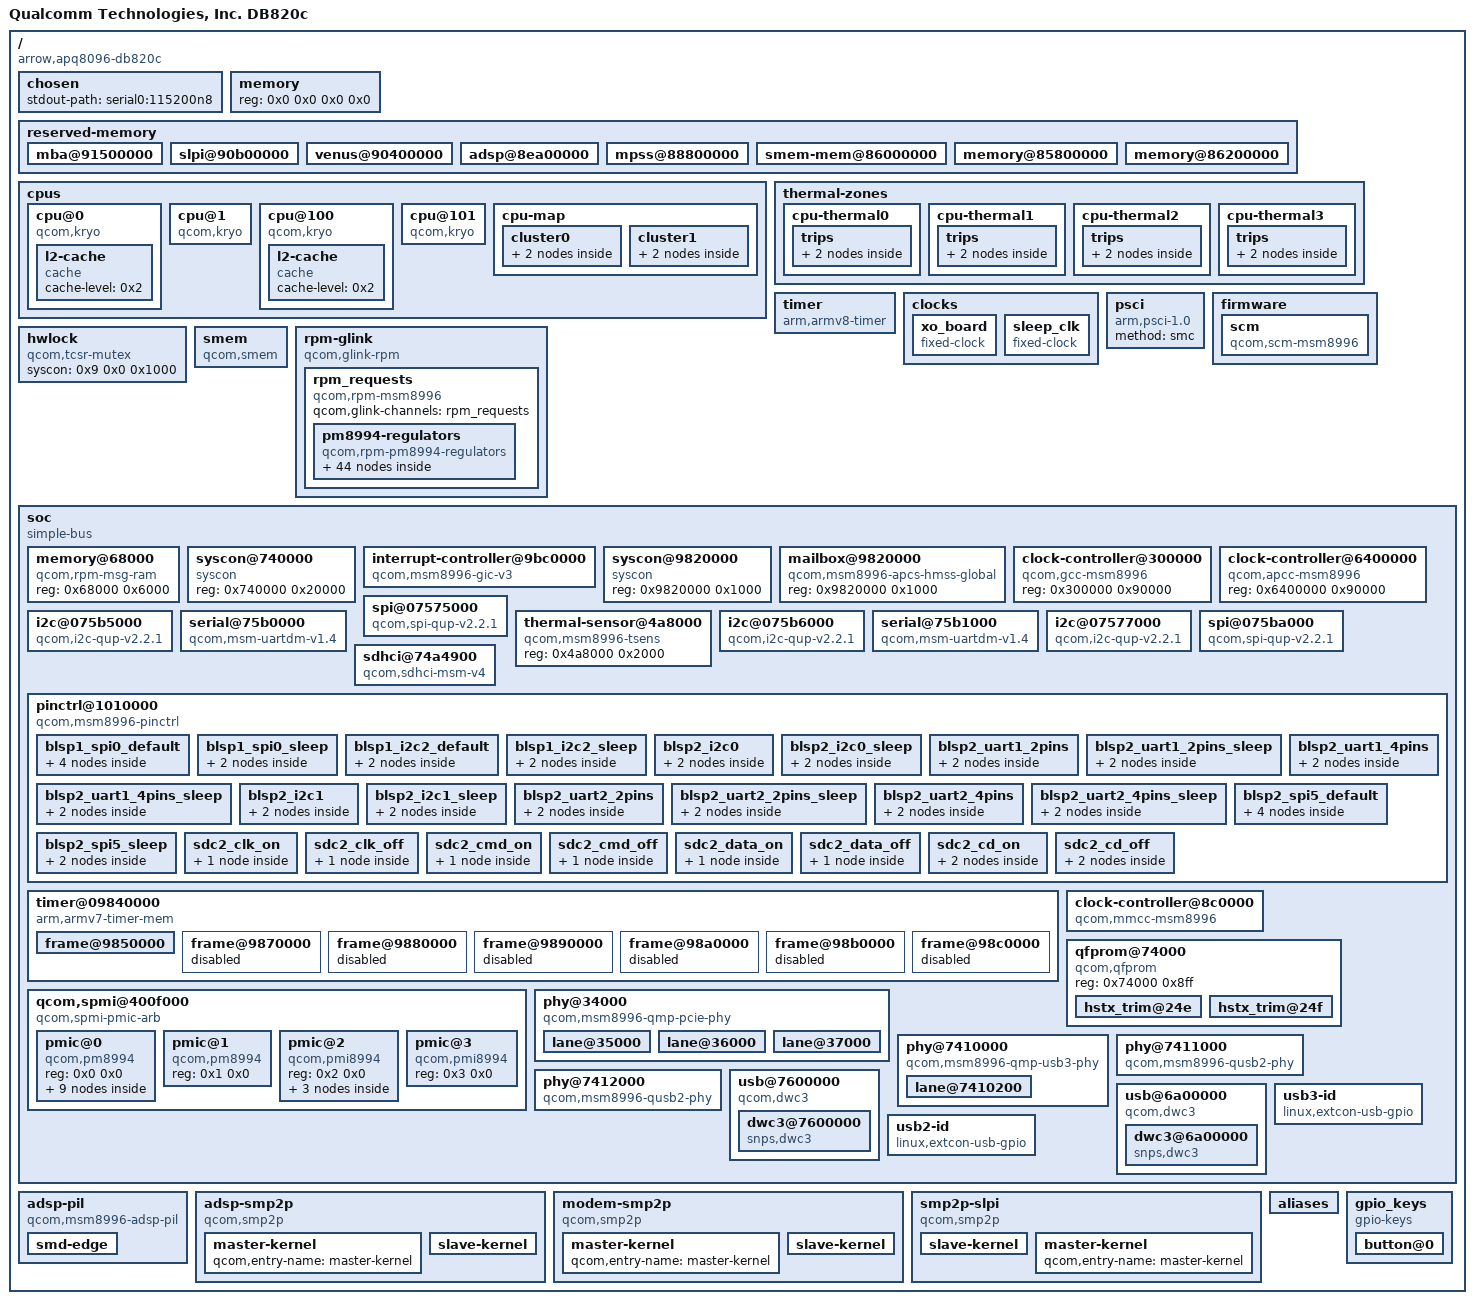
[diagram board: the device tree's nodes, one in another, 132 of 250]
/dts-v1/;

/ {
	model = "Qualcomm Technologies, Inc. DB820c";
	interrupt-parent = <0x1>;
	#address-cells = <0x2>;
	#size-cells = <0x2>;
	compatible = "arrow,apq8096-db820c", "qcom,apq8096-sbc";

	chosen {
		stdout-path = "serial0:115200n8";
	};

	memory {
		device_type = "memory";
		reg = <0x0 0x0 0x0 0x0>;
	};

	reserved-memory {
		#address-cells = <0x2>;
		#size-cells = <0x2>;
		ranges;

		mba@91500000 {
			reg = <0x0 0x91500000 0x0 0x200000>;
			no-map;
			phandle = <0x3e>;
		};

		slpi@90b00000 {
			reg = <0x0 0x90b00000 0x0 0xa00000>;
			no-map;
			phandle = <0x3f>;
		};

		venus@90400000 {
			reg = <0x0 0x90400000 0x0 0x700000>;
			no-map;
			phandle = <0x40>;
		};

		adsp@8ea00000 {
			reg = <0x0 0x8ea00000 0x0 0x1a00000>;
			no-map;
			phandle = <0x3a>;
		};

		mpss@88800000 {
			reg = <0x0 0x88800000 0x0 0x6200000>;
			no-map;
			phandle = <0x41>;
		};

		smem-mem@86000000 {
			reg = <0x0 0x86000000 0x0 0x200000>;
			no-map;
			phandle = <0xa>;
		};

		memory@85800000 {
			reg = <0x0 0x85800000 0x0 0x800000>;
			no-map;
		};

		memory@86200000 {
			reg = <0x0 0x86200000 0x0 0x2600000>;
			no-map;
		};
	};

	cpus {
		#address-cells = <0x2>;
		#size-cells = <0x0>;

		cpu@0 {
			device_type = "cpu";
			compatible = "qcom,kryo";
			reg = <0x0 0x0>;
			enable-method = "psci";
			next-level-cache = <0x2>;
			phandle = <0x4>;

			l2-cache {
				compatible = "cache";
				cache-level = <0x2>;
				phandle = <0x2>;
			};
		};

		cpu@1 {
			device_type = "cpu";
			compatible = "qcom,kryo";
			reg = <0x0 0x1>;
			enable-method = "psci";
			next-level-cache = <0x2>;
			phandle = <0x5>;
		};

		cpu@100 {
			device_type = "cpu";
			compatible = "qcom,kryo";
			reg = <0x0 0x100>;
			enable-method = "psci";
			next-level-cache = <0x3>;
			phandle = <0x6>;

			l2-cache {
				compatible = "cache";
				cache-level = <0x2>;
				phandle = <0x3>;
			};
		};

		cpu@101 {
			device_type = "cpu";
			compatible = "qcom,kryo";
			reg = <0x0 0x101>;
			enable-method = "psci";
			next-level-cache = <0x3>;
			phandle = <0x7>;
		};

		cpu-map {

			cluster0 {

				core0 {
					cpu = <0x4>;
				};

				core1 {
					cpu = <0x5>;
				};
			};

			cluster1 {

				core0 {
					cpu = <0x6>;
				};

				core1 {
					cpu = <0x7>;
				};
			};
		};
	};

	thermal-zones {

		cpu-thermal0 {
			polling-delay-passive = <0xfa>;
			polling-delay = <0x3e8>;
			thermal-sensors = <0x8 0x3>;

			trips {

				trip0 {
					temperature = <0x124f8>;
					hysteresis = <0x7d0>;
					type = "passive";
					phandle = <0x42>;
				};

				trip1 {
					temperature = <0x1adb0>;
					hysteresis = <0x7d0>;
					type = "critical";
					phandle = <0x43>;
				};
			};
		};

		cpu-thermal1 {
			polling-delay-passive = <0xfa>;
			polling-delay = <0x3e8>;
			thermal-sensors = <0x8 0x5>;

			trips {

				trip0 {
					temperature = <0x124f8>;
					hysteresis = <0x7d0>;
					type = "passive";
					phandle = <0x44>;
				};

				trip1 {
					temperature = <0x1adb0>;
					hysteresis = <0x7d0>;
					type = "critical";
					phandle = <0x45>;
				};
			};
		};

		cpu-thermal2 {
			polling-delay-passive = <0xfa>;
			polling-delay = <0x3e8>;
			thermal-sensors = <0x8 0x8>;

			trips {

				trip0 {
					temperature = <0x124f8>;
					hysteresis = <0x7d0>;
					type = "passive";
					phandle = <0x46>;
				};

				trip1 {
					temperature = <0x1adb0>;
					hysteresis = <0x7d0>;
					type = "critical";
					phandle = <0x47>;
				};
			};
		};

		cpu-thermal3 {
			polling-delay-passive = <0xfa>;
			polling-delay = <0x3e8>;
			thermal-sensors = <0x8 0xa>;

			trips {

				trip0 {
					temperature = <0x124f8>;
					hysteresis = <0x7d0>;
					type = "passive";
					phandle = <0x48>;
				};

				trip1 {
					temperature = <0x1adb0>;
					hysteresis = <0x7d0>;
					type = "critical";
					phandle = <0x49>;
				};
			};
		};
	};

	timer {
		compatible = "arm,armv8-timer";
		interrupts = <0x1 0xd 0xf08 0x1 0xe 0xf08 0x1 0xb 0xf08 0x1 0xa 0xf08>;
	};

	clocks {

		xo_board {
			compatible = "fixed-clock";
			#clock-cells = <0x0>;
			clock-frequency = <0x124f800>;
			clock-output-names = "xo_board";
			phandle = <0x1f>;
		};

		sleep_clk {
			compatible = "fixed-clock";
			#clock-cells = <0x0>;
			clock-frequency = <0x7ffc>;
			clock-output-names = "sleep_clk";
			phandle = <0x4a>;
		};
	};

	psci {
		compatible = "arm,psci-1.0";
		method = "smc";
	};

	firmware {

		scm {
			compatible = "qcom,scm-msm8996";
		};
	};

	hwlock {
		compatible = "qcom,tcsr-mutex";
		syscon = <0x9 0x0 0x1000>;
		#hwlock-cells = <0x1>;
		phandle = <0xb>;
	};

	smem {
		compatible = "qcom,smem";
		memory-region = <0xa>;
		hwlocks = <0xb 0x3>;
	};

	rpm-glink {
		compatible = "qcom,glink-rpm";
		interrupts = <0x0 0xa8 0x1>;
		qcom,rpm-msg-ram = <0xc>;
		mboxes = <0xd 0x0>;

		rpm_requests {
			compatible = "qcom,rpm-msm8996";
			qcom,glink-channels = "rpm_requests";

			pm8994-regulators {
				compatible = "qcom,rpm-pm8994-regulators";
				vdd_l1-supply = <0xe>;
				vdd_l2_l26_l28-supply = <0xe>;
				vdd_l3_l11-supply = <0xe>;
				vdd_l4_l27_l31-supply = <0xe>;
				vdd_l5_l7-supply = <0xf>;
				vdd_l14_l15-supply = <0xf>;
				vdd_l20_l21-supply = <0xf>;
				vdd_l25-supply = <0xe>;

				s1 {
					phandle = <0x4b>;
				};

				s2 {
					phandle = <0x4c>;
				};

				s3 {
					regulator-min-microvolt = <0x13d620>;
					regulator-max-microvolt = <0x13d620>;
					phandle = <0xe>;
				};

				s4 {
					regulator-min-microvolt = <0x1b7740>;
					regulator-max-microvolt = <0x1b7740>;
					phandle = <0x4d>;
				};

				s5 {
					regulator-min-microvolt = <0x20ce70>;
					regulator-max-microvolt = <0x20ce70>;
					phandle = <0xf>;
				};

				s6 {
					phandle = <0x4e>;
				};

				s7 {
					regulator-min-microvolt = <0xc3500>;
					regulator-max-microvolt = <0xc3500>;
					phandle = <0x4f>;
				};

				s8 {
					phandle = <0x50>;
				};

				s9 {
					phandle = <0x51>;
				};

				s10 {
					phandle = <0x52>;
				};

				s11 {
					phandle = <0x53>;
				};

				s12 {
					phandle = <0x54>;
				};

				l1 {
					regulator-min-microvolt = <0xf4240>;
					regulator-max-microvolt = <0xf4240>;
					phandle = <0x55>;
				};

				l2 {
					regulator-min-microvolt = <0x1312d0>;
					regulator-max-microvolt = <0x1312d0>;
					phandle = <0x56>;
				};

				l3 {
					regulator-min-microvolt = <0xcf850>;
					regulator-max-microvolt = <0xcf850>;
					phandle = <0x57>;
				};

				l4 {
					regulator-min-microvolt = <0x12b128>;
					regulator-max-microvolt = <0x12b128>;
					phandle = <0x58>;
				};

				l5 {
					phandle = <0x59>;
				};

				l6 {
					regulator-min-microvolt = <0x124f80>;
					regulator-max-microvolt = <0x124f80>;
					phandle = <0x5a>;
				};

				l7 {
					phandle = <0x5b>;
				};

				l8 {
					regulator-min-microvolt = <0x1b7740>;
					regulator-max-microvolt = <0x1b7740>;
					phandle = <0x5c>;
				};

				l9 {
					regulator-min-microvolt = <0x1b7740>;
					regulator-max-microvolt = <0x1b7740>;
					phandle = <0x5d>;
				};

				l10 {
					regulator-min-microvolt = <0x1b7740>;
					regulator-max-microvolt = <0x1b7740>;
					phandle = <0x5e>;
				};

				l11 {
					regulator-min-microvolt = <0x118c30>;
					regulator-max-microvolt = <0x118c30>;
					phandle = <0x5f>;
				};

				l12 {
					regulator-min-microvolt = <0x1b7740>;
					regulator-max-microvolt = <0x1b7740>;
					phandle = <0x2c>;
				};

				l13 {
					regulator-min-microvolt = <0x1b7740>;
					regulator-max-microvolt = <0x2d0370>;
					phandle = <0x60>;
				};

				l14 {
					regulator-min-microvolt = <0x1b7740>;
					regulator-max-microvolt = <0x1b7740>;
					phandle = <0x61>;
				};

				l15 {
					regulator-min-microvolt = <0x1b7740>;
					regulator-max-microvolt = <0x1b7740>;
					phandle = <0x62>;
				};

				l16 {
					regulator-min-microvolt = <0x2932e0>;
					regulator-max-microvolt = <0x2932e0>;
					phandle = <0x63>;
				};

				l17 {
					regulator-min-microvolt = <0x2625a0>;
					regulator-max-microvolt = <0x2625a0>;
					phandle = <0x64>;
				};

				l18 {
					regulator-min-microvolt = <0x2932e0>;
					regulator-max-microvolt = <0x2c4020>;
					phandle = <0x65>;
				};

				l19 {
					regulator-min-microvolt = <0x2dc6c0>;
					regulator-max-microvolt = <0x2dc6c0>;
					phandle = <0x66>;
				};

				l20 {
					regulator-min-microvolt = <0x2d0370>;
					regulator-max-microvolt = <0x2d0370>;
					regulator-allow-set-load;
					phandle = <0x67>;
				};

				l21 {
					regulator-min-microvolt = <0x2d0370>;
					regulator-max-microvolt = <0x2d0370>;
					phandle = <0x68>;
				};

				l22 {
					regulator-min-microvolt = <0x325aa0>;
					regulator-max-microvolt = <0x325aa0>;
					phandle = <0x69>;
				};

				l23 {
					regulator-min-microvolt = <0x2ab980>;
					regulator-max-microvolt = <0x2ab980>;
					phandle = <0x6a>;
				};

				l24 {
					regulator-min-microvolt = <0x2eebb8>;
					regulator-max-microvolt = <0x2eebb8>;
					phandle = <0x2d>;
				};

				l25 {
					regulator-min-microvolt = <0x124f80>;
					regulator-max-microvolt = <0x124f80>;
					regulator-allow-set-load;
					phandle = <0x6b>;
				};

				l26 {
					phandle = <0x6c>;
				};

				l27 {
					regulator-min-microvolt = <0xf4240>;
					regulator-max-microvolt = <0xf4240>;
					phandle = <0x6d>;
				};

				l28 {
					regulator-min-microvolt = <0xe1d48>;
					regulator-max-microvolt = <0xe1d48>;
					regulator-allow-set-load;
					phandle = <0x2b>;
				};

				l29 {
					regulator-min-microvolt = <0x2ab980>;
					regulator-max-microvolt = <0x2ab980>;
					phandle = <0x6e>;
				};

				l30 {
					regulator-min-microvolt = <0x1b7740>;
					regulator-max-microvolt = <0x1b7740>;
					phandle = <0x6f>;
				};

				l31 {
					phandle = <0x70>;
				};

				l32 {
					regulator-min-microvolt = <0x1b7740>;
					regulator-max-microvolt = <0x1b7740>;
					phandle = <0x71>;
				};
			};
		};
	};

	soc {
		#address-cells = <0x1>;
		#size-cells = <0x1>;
		ranges = <0x0 0x0 0x0 0xffffffff>;
		compatible = "simple-bus";
		phandle = <0x72>;

		memory@68000 {
			compatible = "qcom,rpm-msg-ram";
			reg = <0x68000 0x6000>;
			phandle = <0xc>;
		};

		syscon@740000 {
			compatible = "syscon";
			reg = <0x740000 0x20000>;
			phandle = <0x9>;
		};

		interrupt-controller@9bc0000 {
			compatible = "qcom,msm8996-gic-v3", "arm,gic-v3";
			#interrupt-cells = <0x3>;
			interrupt-controller;
			#redistributor-regions = <0x1>;
			redistributor-stride = <0x0 0x40000>;
			reg = <0x9bc0000 0x10000 0x9c00000 0x100000>;
			interrupts = <0x1 0x9 0x4>;
			phandle = <0x1>;
		};

		syscon@9820000 {
			compatible = "syscon";
			reg = <0x9820000 0x1000>;
			phandle = <0x3c>;
		};

		mailbox@9820000 {
			compatible = "qcom,msm8996-apcs-hmss-global";
			reg = <0x9820000 0x1000>;
			#mbox-cells = <0x1>;
			phandle = <0xd>;
		};

		clock-controller@300000 {
			compatible = "qcom,gcc-msm8996";
			#clock-cells = <0x1>;
			#reset-cells = <0x1>;
			#power-domain-cells = <0x1>;
			reg = <0x300000 0x90000>;
			phandle = <0x10>;
		};

		clock-controller@6400000 {
			compatible = "qcom,apcc-msm8996";
			reg = <0x6400000 0x90000>;
			#clock-cells = <0x1>;
			phandle = <0x73>;
		};

		spi@07575000 {
			compatible = "qcom,spi-qup-v2.2.1";
			reg = <0x7575000 0x600>;
			interrupts = <0x0 0x5f 0x4>;
			clocks = <0x10 0x6f 0x10 0x6d>;
			clock-names = "core", "iface";
			pinctrl-names = "default", "sleep";
			pinctrl-0 = <0x11>;
			pinctrl-1 = <0x12>;
			#address-cells = <0x1>;
			#size-cells = <0x0>;
			status = "okay";
			label = "LS-SPI0";
			phandle = <0x74>;
		};

		i2c@075b5000 {
			compatible = "qcom,i2c-qup-v2.2.1";
			reg = <0x75b5000 0x1000>;
			interrupts = <0x0 0x65 0x0>;
			clocks = <0x10 0x81 0x10 0x84>;
			clock-names = "iface", "core";
			pinctrl-names = "default", "sleep";
			pinctrl-0 = <0x13>;
			pinctrl-1 = <0x14>;
			#address-cells = <0x1>;
			#size-cells = <0x0>;
			status = "okay";
			label = "HS-I2C2";
			phandle = <0x75>;
		};

		thermal-sensor@4a8000 {
			compatible = "qcom,msm8996-tsens";
			reg = <0x4a8000 0x2000>;
			#thermal-sensor-cells = <0x1>;
			phandle = <0x8>;
		};

		serial@75b0000 {
			compatible = "qcom,msm-uartdm-v1.4", "qcom,msm-uartdm";
			reg = <0x75b0000 0x1000>;
			interrupts = <0x0 0x72 0x4>;
			clocks = <0x10 0x88 0x10 0x81>;
			clock-names = "core", "iface";
			status = "okay";
			label = "LS-UART1";
			pinctrl-names = "default", "sleep";
			pinctrl-0 = <0x15>;
			pinctrl-1 = <0x16>;
			phandle = <0x76>;
		};

		i2c@075b6000 {
			compatible = "qcom,i2c-qup-v2.2.1";
			reg = <0x75b6000 0x1000>;
			interrupts = <0x0 0x66 0x0>;
			clocks = <0x10 0x81 0x10 0x87>;
			clock-names = "iface", "core";
			pinctrl-names = "default", "sleep";
			pinctrl-0 = <0x17>;
			pinctrl-1 = <0x18>;
			#address-cells = <0x1>;
			#size-cells = <0x0>;
			status = "okay";
			label = "LS-I2C1";
			phandle = <0x77>;
		};

		serial@75b1000 {
			compatible = "qcom,msm-uartdm-v1.4", "qcom,msm-uartdm";
			reg = <0x75b1000 0x1000>;
			interrupts = <0x0 0x73 0x4>;
			clocks = <0x10 0x8b 0x10 0x81>;
			clock-names = "core", "iface";
			status = "okay";
			label = "LS-UART0";
			pinctrl-names = "default", "sleep";
			pinctrl-0 = <0x19>;
			pinctrl-1 = <0x1a>;
			phandle = <0x78>;
		};

		i2c@07577000 {
			compatible = "qcom,i2c-qup-v2.2.1";
			reg = <0x7577000 0x1000>;
			interrupts = <0x0 0x61 0x0>;
			clocks = <0x10 0x6d 0x10 0x76>;
			clock-names = "iface", "core";
			pinctrl-names = "default", "sleep";
			pinctrl-0 = <0x1b>;
			pinctrl-1 = <0x1c>;
			#address-cells = <0x1>;
			#size-cells = <0x0>;
			status = "okay";
			label = "LS-I2C0";
			phandle = <0x79>;
		};

		spi@075ba000 {
			compatible = "qcom,spi-qup-v2.2.1";
			reg = <0x75ba000 0x600>;
			interrupts = <0x0 0x6a 0x4>;
			clocks = <0x10 0x92 0x10 0x81>;
			clock-names = "core", "iface";
			pinctrl-names = "default", "sleep";
			pinctrl-0 = <0x1d>;
			pinctrl-1 = <0x1e>;
			#address-cells = <0x1>;
			#size-cells = <0x0>;
			status = "okay";
			label = "HS-SPI1";
			phandle = <0x7a>;
		};

		sdhci@74a4900 {
			status = "okay";
			compatible = "qcom,sdhci-msm-v4";
			reg = <0x74a4900 0x314 0x74a4000 0x800>;
			reg-names = "hc_mem", "core_mem";
			interrupts = <0x0 0x7d 0x0 0x0 0xdd 0x0>;
			interrupt-names = "hc_irq", "pwr_irq";
			clock-names = "iface", "core", "xo";
			clocks = <0x10 0x68 0x10 0x67 0x1f>;
			bus-width = <0x4>;
			pinctrl-names = "default", "sleep";
			pinctrl-0 = <0x20 0x21 0x22 0x23>;
			pinctrl-1 = <0x24 0x25 0x26 0x27>;
			cd-gpios = <0x28 0x26 0x1>;
			phandle = <0x7b>;
		};

		pinctrl@1010000 {
			compatible = "qcom,msm8996-pinctrl";
			reg = <0x1010000 0x300000>;
			interrupts = <0x0 0xd0 0x4>;
			gpio-controller;
			#gpio-cells = <0x2>;
			interrupt-controller;
			#interrupt-cells = <0x2>;
			phandle = <0x28>;

			blsp1_spi0_default {
				phandle = <0x11>;

				pinmux {
					function = "blsp_spi1";
					pins = "gpio0", "gpio1", "gpio3";
				};

				pinmux_cs {
					function = "gpio";
					pins = "gpio2";
				};

				pinconf {
					pins = "gpio0", "gpio1", "gpio3";
					drive-strength = <0xc>;
					bias-disable;
				};

				pinconf_cs {
					pins = "gpio2";
					drive-strength = <0x10>;
					bias-disable;
					output-high;
				};
			};

			blsp1_spi0_sleep {
				phandle = <0x12>;

				pinmux {
					function = "gpio";
					pins = "gpio0", "gpio1", "gpio2", "gpio3";
				};

				pinconf {
					pins = "gpio0", "gpio1", "gpio2", "gpio3";
					drive-strength = <0x2>;
					bias-pull-down;
				};
			};

			blsp1_i2c2_default {
				phandle = <0x1b>;

				pinmux {
					function = "blsp_i2c3";
					pins = "gpio47", "gpio48";
				};

				pinconf {
					pins = "gpio47", "gpio48";
					drive-strength = <0x10>;
					bias-disable = <0x0>;
				};
			};

			blsp1_i2c2_sleep {
				phandle = <0x1c>;

				pinmux {
					function = "gpio";
					pins = "gpio47", "gpio48";
				};

				pinconf {
					pins = "gpio47", "gpio48";
					drive-strength = <0x2>;
					bias-disable = <0x0>;
				};
			};

			blsp2_i2c0 {
				phandle = <0x13>;

				pinmux {
					function = "blsp_i2c7";
					pins = "gpio55", "gpio56";
				};

				pinconf {
					pins = "gpio55", "gpio56";
					drive-strength = <0x10>;
					bias-disable;
				};
			};

			blsp2_i2c0_sleep {
				phandle = <0x14>;

				pinmux {
					function = "gpio";
					pins = "gpio55", "gpio56";
				};

				pinconf {
					pins = "gpio55", "gpio56";
					drive-strength = <0x2>;
					bias-disable;
				};
			};

			blsp2_uart1_2pins {
				phandle = <0x15>;

				pinmux {
					function = "blsp_uart8";
					pins = "gpio4", "gpio5";
				};

				pinconf {
					pins = "gpio4", "gpio5";
					drive-strength = <0x10>;
					bias-disable;
				};
			};

			blsp2_uart1_2pins_sleep {
				phandle = <0x16>;

				pinmux {
					function = "gpio";
					pins = "gpio4", "gpio5";
				};

				pinconf {
					pins = "gpio4", "gpio5";
					drive-strength = <0x2>;
					bias-disable;
				};
			};

			blsp2_uart1_4pins {
				phandle = <0x7c>;

				pinmux {
					function = "blsp_uart8";
					pins = "gpio4", "gpio5", "gpio6", "gpio7";
				};

				pinconf {
					pins = "gpio4", "gpio5", "gpio6", "gpio7";
					drive-strength = <0x10>;
					bias-disable;
				};
			};

			blsp2_uart1_4pins_sleep {
				phandle = <0x7d>;

				pinmux {
					function = "gpio";
					pins = "gpio4", "gpio5", "gpio6", "gpio7";
				};

				pinconf {
					pins = "gpio4", "gpiio5", "gpio6", "gpio7";
					drive-strength = <0x2>;
					bias-disable;
				};
			};

			blsp2_i2c1 {
				phandle = <0x17>;

				pinmux {
					function = "blsp_i2c8";
					pins = "gpio6", "gpio7";
				};

				pinconf {
					pins = "gpio6", "gpio7";
					drive-strength = <0x10>;
					bias-disable;
				};
			};

			blsp2_i2c1_sleep {
				phandle = <0x18>;

				pinmux {
					function = "gpio";
					pins = "gpio6", "gpio7";
				};

				pinconf {
					pins = "gpio6", "gpio7";
					drive-strength = <0x2>;
					bias-disable;
				};
			};

			blsp2_uart2_2pins {
				phandle = <0x7e>;

				pinmux {
					function = "blsp_uart9";
					pins = "gpio49", "gpio50";
				};

				pinconf {
					pins = "gpio49", "gpio50";
					drive-strength = <0x10>;
					bias-disable;
				};
			};

			blsp2_uart2_2pins_sleep {
				phandle = <0x7f>;

				pinmux {
					function = "gpio";
					pins = "gpio49", "gpio50";
				};

				pinconf {
					pins = "gpio49", "gpio50";
					drive-strength = <0x2>;
					bias-disable;
				};
			};

			blsp2_uart2_4pins {
				phandle = <0x19>;

				pinmux {
					function = "blsp_uart9";
					pins = "gpio49", "gpio50", "gpio51", "gpio52";
				};

				pinconf {
					pins = "gpio49", "gpio50", "gpio51", "gpio52";
					drive-strength = <0x10>;
					bias-disable;
				};
			};

			blsp2_uart2_4pins_sleep {
				phandle = <0x1a>;

				pinmux {
					function = "gpio";
					pins = "gpio49", "gpio50", "gpio51", "gpio52";
				};

				pinconf {
					pins = "gpio49", "gpio50", "gpio51", "gpio52";
					drive-strength = <0x2>;
					bias-disable;
				};
			};

			blsp2_spi5_default {
				phandle = <0x1d>;

				pinmux {
					function = "blsp_spi12";
					pins = "gpio85", "gpio86", "gpio88";
				};

				pinmux_cs {
					function = "gpio";
					pins = "gpio87";
				};

				pinconf {
					pins = "gpio85", "gpio86", "gpio88";
					drive-strength = <0xc>;
					bias-disable;
				};

				pinconf_cs {
					pins = "gpio87";
					drive-strength = <0x10>;
					bias-disable;
					output-high;
				};
			};

			blsp2_spi5_sleep {
				phandle = <0x1e>;

				pinmux {
					function = "gpio";
					pins = "gpio85", "gpio86", "gpio87", "gpio88";
				};

				pinconf {
					pins = "gpio85", "gpio86", "gpio87", "gpio88";
					drive-strength = <0x2>;
					bias-pull-down;
				};
			};

			sdc2_clk_on {
				phandle = <0x20>;

				config {
					pins = "sdc2_clk";
					bias-disable;
					drive-strength = <0x10>;
				};
			};

			sdc2_clk_off {
				phandle = <0x24>;

				config {
					pins = "sdc2_clk";
					bias-disable;
					drive-strength = <0x2>;
				};
			};

			sdc2_cmd_on {
				phandle = <0x21>;

				config {
					pins = "sdc2_cmd";
					bias-pull-up;
					drive-strength = <0xa>;
				};
			};

			sdc2_cmd_off {
				phandle = <0x25>;

				config {
					pins = "sdc2_cmd";
					bias-pull-up;
					drive-strength = <0x2>;
				};
			};

			sdc2_data_on {
				phandle = <0x22>;

				config {
					pins = "sdc2_data";
					bias-pull-up;
					drive-strength = <0xa>;
				};
			};

			sdc2_data_off {
				phandle = <0x26>;

				config {
					pins = "sdc2_data";
					bias-pull-up;
					drive-strength = <0x2>;
				};
			};

			sdc2_cd_on {
				phandle = <0x23>;

				mux {
					pins = "gpio38";
					function = "gpio";
				};

				config {
					pins = "gpio38";
					bias-pull-up;
					drive-strength = <0x10>;
				};
			};

			sdc2_cd_off {
				phandle = <0x27>;

				mux {
					pins = "gpio38";
					function = "gpio";
				};

				config {
					pins = "gpio38";
					bias-pull-up;
					drive-strength = <0x2>;
				};
			};
		};

		timer@09840000 {
			#address-cells = <0x1>;
			#size-cells = <0x1>;
			ranges;
			compatible = "arm,armv7-timer-mem";
			reg = <0x9840000 0x1000>;
			clock-frequency = <0x124f800>;

			frame@9850000 {
				frame-number = <0x0>;
				interrupts = <0x0 0x1f 0x4 0x0 0x1e 0x4>;
				reg = <0x9850000 0x1000 0x9860000 0x1000>;
			};

			frame@9870000 {
				frame-number = <0x1>;
				interrupts = <0x0 0x20 0x4>;
				reg = <0x9870000 0x1000>;
				status = "disabled";
			};

			frame@9880000 {
				frame-number = <0x2>;
				interrupts = <0x0 0x21 0x4>;
				reg = <0x9880000 0x1000>;
				status = "disabled";
			};

			frame@9890000 {
				frame-number = <0x3>;
				interrupts = <0x0 0x22 0x4>;
				reg = <0x9890000 0x1000>;
				status = "disabled";
			};

			frame@98a0000 {
				frame-number = <0x4>;
				interrupts = <0x0 0x23 0x4>;
				reg = <0x98a0000 0x1000>;
				status = "disabled";
			};

			frame@98b0000 {
				frame-number = <0x5>;
				interrupts = <0x0 0x24 0x4>;
				reg = <0x98b0000 0x1000>;
				status = "disabled";
			};

			frame@98c0000 {
				frame-number = <0x6>;
				interrupts = <0x0 0x25 0x4>;
				reg = <0x98c0000 0x1000>;
				status = "disabled";
			};
		};

		qcom,spmi@400f000 {
			compatible = "qcom,spmi-pmic-arb";
			reg = <0x400f000 0x1000 0x4400000 0x800000 0x4c00000 0x800000 0x5800000 0x200000 0x400a000 0x2100>;
			reg-names = "core", "chnls", "obsrvr", "intr", "cnfg";
			interrupt-names = "periph_irq";
			interrupts = <0x0 0x146 0x4>;
			qcom,ee = <0x0>;
			qcom,channel = <0x0>;
			#address-cells = <0x2>;
			#size-cells = <0x0>;
			interrupt-controller;
			#interrupt-cells = <0x4>;
			phandle = <0x80>;

			pmic@0 {
				compatible = "qcom,pm8994", "qcom,spmi-pmic";
				reg = <0x0 0x0>;
				#address-cells = <0x1>;
				#size-cells = <0x0>;

				rtc@6000 {
					compatible = "qcom,pm8941-rtc";
					reg = <0x6000 0x6100>;
					reg-names = "rtc", "alarm";
					interrupts = <0x0 0x61 0x1 0x1>;
				};

				gpios@c000 {
					compatible = "qcom,pm8994-gpio";
					reg = <0xc000>;
					gpio-controller;
					#gpio-cells = <0x2>;
					interrupts = <0x0 0xc0 0x0 0x0 0x0 0xc1 0x0 0x0 0x0 0xc2 0x0 0x0 0x0 0xc3 0x0 0x0 0x0 0xc4 0x0 0x0 0x0 0xc5 0x0 0x0 0x0 0xc6 0x0 0x0 0x0 0xc7 0x0 0x0 0x0 0xc8 0x0 0x0 0x0 0xc9 0x0 0x0 0x0 0xca 0x0 0x0 0x0 0xcb 0x0 0x0 0x0 0xcc 0x0 0x0 0x0 0xcd 0x0 0x0 0x0 0xce 0x0 0x0 0x0 0xcf 0x0 0x0 0x0 0xd0 0x0 0x0 0x0 0xd1 0x0 0x0 0x0 0xd2 0x0 0x0 0x0 0xd3 0x0 0x0 0x0 0xd4 0x0 0x0 0x0 0xd5 0x0 0x0>;
					pinctrl-names = "default";
					pinctrl-0 = <0x29>;
					phandle = <0x35>;

					pm8994_gpio5 {
						phandle = <0x29>;

						pinconf {
							pins = "gpio5";
							output-low;
							power-source = <0x2>;
						};
					};

					pm8996_gpio2 {
						phandle = <0x3d>;

						pinconf {
							pins = "gpio2";
							function = "normal";
							input-enable;
							drive-push-pull;
							bias-pull-up;
							qcom,drive-strength = <0x0>;
							power-source = <0x2>;
						};
					};

					pm8996_gpio22 {
						phandle = <0x36>;

						pinconf {
							pins = "gpio22";
							function = "normal";
							input-enable;
							bias-pull-down;
							qcom,drive-strength = <0x0>;
							power-source = <0x2>;
						};
					};
				};

				mpps@a000 {
					compatible = "qcom,pm8994-mpp";
					reg = <0xa000>;
					gpio-controller;
					#gpio-cells = <0x2>;
					interrupts = <0x0 0xa0 0x0 0x0 0x0 0xa1 0x0 0x0 0x0 0xa2 0x0 0x0 0x0 0xa3 0x0 0x0 0x0 0xa4 0x0 0x0 0x0 0xa5 0x0 0x0 0x0 0xa6 0x0 0x0 0x0 0xa7 0x0 0x0>;
					phandle = <0x81>;
				};
			};

			pmic@1 {
				compatible = "qcom,pm8994", "qcom,spmi-pmic";
				reg = <0x1 0x0>;
				#address-cells = <0x1>;
				#size-cells = <0x0>;
			};

			pmic@2 {
				compatible = "qcom,pmi8994", "qcom,spmi-pmic";
				reg = <0x2 0x0>;
				#address-cells = <0x1>;
				#size-cells = <0x0>;

				gpios@c000 {
					compatible = "qcom,pmi8994-gpio", "qcom,spmi-gpio";
					reg = <0xc000>;
					gpio-controller;
					#gpio-cells = <0x2>;
					interrupts = <0x2 0xc0 0x0 0x0 0x2 0xc1 0x0 0x0 0x2 0xc2 0x0 0x0 0x2 0xc3 0x0 0x0 0x2 0xc4 0x0 0x0 0x2 0xc5 0x0 0x0 0x2 0xc6 0x0 0x0 0x2 0xc7 0x0 0x0 0x2 0xc8 0x0 0x0 0x2 0xc9 0x0 0x0>;
					phandle = <0x37>;

					pmi8996_gpio6 {
						phandle = <0x38>;

						pinconf {
							pins = "gpio6";
							function = "normal";
							input-enable;
							bias-pull-down;
							qcom,drive-strength = <0x0>;
							power-source = <0x2>;
						};
					};
				};
			};

			pmic@3 {
				compatible = "qcom,pmi8994", "qcom,spmi-pmic";
				reg = <0x3 0x0>;
				#address-cells = <0x1>;
				#size-cells = <0x0>;
			};
		};

		clock-controller@8c0000 {
			compatible = "qcom,mmcc-msm8996";
			#clock-cells = <0x1>;
			#reset-cells = <0x1>;
			#power-domain-cells = <0x1>;
			reg = <0x8c0000 0x40000>;
			assigned-clocks = <0x2a 0xf 0x2a 0x3 0x2a 0x7 0x2a 0x9 0x2a 0xb>;
			assigned-clock-rates = <0x25317c00 0x30479e80 0x3a699d00 0x39387000 0x312c8040>;
			phandle = <0x2a>;
		};

		qfprom@74000 {
			compatible = "qcom,qfprom";
			reg = <0x74000 0x8ff>;
			#address-cells = <0x1>;
			#size-cells = <0x1>;

			hstx_trim@24e {
				reg = <0x24e 0x2>;
				bits = <0x5 0x4>;
				phandle = <0x2e>;
			};

			hstx_trim@24f {
				reg = <0x24f 0x1>;
				bits = <0x1 0x4>;
				phandle = <0x2f>;
			};
		};

		phy@34000 {
			compatible = "qcom,msm8996-qmp-pcie-phy";
			reg = <0x34000 0x488>;
			#clock-cells = <0x1>;
			#address-cells = <0x1>;
			#size-cells = <0x1>;
			ranges;
			clocks = <0x10 0xc0 0x10 0xbf 0x10 0xd8>;
			clock-names = "aux", "cfg_ahb", "ref";
			vdda-phy-supply = <0x2b>;
			vdda-pll-supply = <0x2c>;
			resets = <0x10 0x55 0x10 0x65 0x10 0x66>;
			reset-names = "phy", "common", "cfg";
			status = "okay";

			lane@35000 {
				reg = <0x35000 0x130 0x35200 0x200 0x35400 0x1dc>;
				#phy-cells = <0x0>;
				clock-output-names = "pcie_0_pipe_clk_src";
				clocks = <0x10 0xb4>;
				clock-names = "pipe0";
				resets = <0x10 0x50>;
				reset-names = "lane0";
				phandle = <0x82>;
			};

			lane@36000 {
				reg = <0x36000 0x130 0x36200 0x200 0x36400 0x1dc>;
				#phy-cells = <0x0>;
				clock-output-names = "pcie_1_pipe_clk_src";
				clocks = <0x10 0xb9>;
				clock-names = "pipe1";
				resets = <0x10 0x52>;
				reset-names = "lane1";
				phandle = <0x83>;
			};

			lane@37000 {
				reg = <0x37000 0x130 0x37200 0x200 0x37400 0x1dc>;
				#phy-cells = <0x0>;
				clock-output-names = "pcie_2_pipe_clk_src";
				clocks = <0x10 0xbe>;
				clock-names = "pipe2";
				resets = <0x10 0x54>;
				reset-names = "lane2";
				phandle = <0x84>;
			};
		};

		phy@7410000 {
			compatible = "qcom,msm8996-qmp-usb3-phy";
			reg = <0x7410000 0x1c4>;
			#clock-cells = <0x1>;
			#address-cells = <0x1>;
			#size-cells = <0x1>;
			ranges;
			clocks = <0x10 0x5e 0x10 0x63 0x10 0xd5>;
			clock-names = "aux", "cfg_ahb", "ref";
			vdda-phy-supply = <0x2b>;
			vdda-pll-supply = <0x2c>;
			resets = <0x10 0x67 0x10 0x68>;
			reset-names = "phy", "common";
			status = "okay";

			lane@7410200 {
				reg = <0x7410200 0x200 0x7410400 0x130 0x7410600 0x1a8>;
				#phy-cells = <0x0>;
				clock-output-names = "usb3_phy_pipe_clk_src";
				clocks = <0x10 0x5f>;
				clock-names = "pipe0";
				phandle = <0x33>;
			};
		};

		phy@7411000 {
			compatible = "qcom,msm8996-qusb2-phy";
			reg = <0x7411000 0x180>;
			#phy-cells = <0x0>;
			clocks = <0x10 0x63 0x10 0xda>;
			clock-names = "cfg_ahb", "ref";
			vdda-pll-supply = <0x2c>;
			vdda-phy-dpdm-supply = <0x2d>;
			resets = <0x10 0x9>;
			nvmem-cells = <0x2e>;
			status = "okay";
			phandle = <0x32>;
		};

		phy@7412000 {
			compatible = "qcom,msm8996-qusb2-phy";
			reg = <0x7412000 0x180>;
			#phy-cells = <0x0>;
			clocks = <0x10 0x63 0x10 0xd9>;
			clock-names = "cfg_ahb", "ref";
			vdda-pll-supply = <0x2c>;
			vdda-phy-dpdm-supply = <0x2d>;
			resets = <0x10 0xa>;
			nvmem-cells = <0x2f>;
			status = "okay";
			phandle = <0x30>;
		};

		usb@7600000 {
			compatible = "qcom,dwc3";
			#address-cells = <0x1>;
			#size-cells = <0x1>;
			ranges;
			clocks = <0x10 0x55 0x10 0x60 0x10 0x62 0x10 0x61 0x10 0x63>;
			assigned-clocks = <0x10 0x62 0x10 0x60>;
			assigned-clock-rates = <0x124f800 0x3938700>;
			power-domains = <0x10 0x4>;
			status = "okay";
			phandle = <0x85>;

			dwc3@7600000 {
				compatible = "snps,dwc3";
				reg = <0x7600000 0xcc00>;
				interrupts = <0x0 0x8a 0x0>;
				phys = <0x30>;
				phy-names = "usb2-phy";
				extcon = <0x31>;
				dr_mode = "otg";
				maximum-speed = "high-speed";
			};
		};

		usb@6a00000 {
			compatible = "qcom,dwc3";
			#address-cells = <0x1>;
			#size-cells = <0x1>;
			ranges;
			clocks = <0x10 0x51 0x10 0x5b 0x10 0xd2 0x10 0x5d 0x10 0x5c 0x10 0x63>;
			assigned-clocks = <0x10 0x5d 0x10 0x5b>;
			assigned-clock-rates = <0x124f800 0x7270e00>;
			power-domains = <0x10 0x4>;
			status = "okay";
			phandle = <0x86>;

			dwc3@6a00000 {
				compatible = "snps,dwc3";
				reg = <0x6a00000 0xcc00>;
				interrupts = <0x0 0x83 0x0>;
				phys = <0x32 0x33>;
				phy-names = "usb2-phy", "usb3-phy";
				extcon = <0x34>;
				dr_mode = "otg";
			};
		};

		usb3-id {
			compatible = "linux,extcon-usb-gpio";
			id-gpio = <0x35 0x16 0x0>;
			pinctrl-names = "default";
			pinctrl-0 = <0x36>;
			phandle = <0x34>;
		};

		usb2-id {
			compatible = "linux,extcon-usb-gpio";
			id-gpio = <0x37 0x6 0x0>;
			pinctrl-names = "default";
			pinctrl-0 = <0x38>;
			phandle = <0x31>;
		};
	};

	adsp-pil {
		compatible = "qcom,msm8996-adsp-pil";
		interrupts-extended = <0x1 0x0 0xa2 0x1 0x39 0x0 0x1 0x39 0x1 0x1 0x39 0x2 0x1 0x39 0x3 0x1>;
		interrupt-names = "wdog", "fatal", "ready", "handover", "stop-ack";
		clocks = <0x1f>;
		clock-names = "xo";
		memory-region = <0x3a>;
		qcom,smem-states = <0x3b 0x0>;
		qcom,smem-state-names = "stop";

		smd-edge {
			interrupts = <0x0 0x9c 0x1>;
			label = "lpass";
			qcom,ipc = <0x3c 0x10 0x8>;
			qcom,smd-edge = <0x1>;
			qcom,remote-pid = <0x2>;
		};
	};

	adsp-smp2p {
		compatible = "qcom,smp2p";
		qcom,smem = <0x1bb 0x1ad>;
		interrupts = <0x0 0x9e 0x1>;
		qcom,ipc = <0x3c 0x10 0xa>;
		qcom,local-pid = <0x0>;
		qcom,remote-pid = <0x2>;

		master-kernel {
			qcom,entry-name = "master-kernel";
			#qcom,smem-state-cells = <0x1>;
			phandle = <0x3b>;
		};

		slave-kernel {
			qcom,entry-name = "slave-kernel";
			interrupt-controller;
			#interrupt-cells = <0x2>;
			phandle = <0x39>;
		};
	};

	modem-smp2p {
		compatible = "qcom,smp2p";
		qcom,smem = <0x1b3 0x1ac>;
		interrupts = <0x0 0x1c3 0x1>;
		qcom,ipc = <0x3c 0x10 0xe>;
		qcom,local-pid = <0x0>;
		qcom,remote-pid = <0x1>;

		master-kernel {
			qcom,entry-name = "master-kernel";
			#qcom,smem-state-cells = <0x1>;
			phandle = <0x87>;
		};

		slave-kernel {
			qcom,entry-name = "slave-kernel";
			interrupt-controller;
			#interrupt-cells = <0x2>;
			phandle = <0x88>;
		};
	};

	smp2p-slpi {
		compatible = "qcom,smp2p";
		qcom,smem = <0x1e1 0x1ae>;
		interrupts = <0x0 0xb2 0x1>;
		qcom,ipc = <0x3c 0x10 0x1a>;
		qcom,local-pid = <0x0>;
		qcom,remote-pid = <0x3>;

		slave-kernel {
			qcom,entry-name = "slave-kernel";
			interrupt-controller;
			#interrupt-cells = <0x2>;
			phandle = <0x89>;
		};

		master-kernel {
			qcom,entry-name = "master-kernel";
			#qcom,smem-state-cells = <0x1>;
			phandle = <0x8a>;
		};
	};

	aliases {
		serial0 = "/soc/serial@75b0000";
		serial1 = "/soc/serial@75b1000";
		i2c0 = "/soc/i2c@07577000";
		i2c1 = "/soc/i2c@075b6000";
		i2c2 = "/soc/i2c@075b5000";
		spi0 = "/soc/spi@07575000";
		spi1 = "/soc/spi@075ba000";
	};

	gpio_keys {
		compatible = "gpio-keys";
		#address-cells = <0x1>;
		#size-cells = <0x0>;
		autorepeat;
		pinctrl-names = "default";
		pinctrl-0 = <0x3d>;

		button@0 {
			label = "Volume Up";
			linux,code = <0x73>;
			gpios = <0x35 0x2 0x1>;
		};
	};

	__symbols__ {
		mba_region = "/reserved-memory/mba@91500000";
		slpi_region = "/reserved-memory/slpi@90b00000";
		venus_region = "/reserved-memory/venus@90400000";
		adsp_region = "/reserved-memory/adsp@8ea00000";
		mpss_region = "/reserved-memory/mpss@88800000";
		smem_mem = "/reserved-memory/smem-mem@86000000";
		CPU0 = "/cpus/cpu@0";
		L2_0 = "/cpus/cpu@0/l2-cache";
		CPU1 = "/cpus/cpu@1";
		CPU2 = "/cpus/cpu@100";
		L2_1 = "/cpus/cpu@100/l2-cache";
		CPU3 = "/cpus/cpu@101";
		cpu_alert0 = "/thermal-zones/cpu-thermal0/trips/trip0";
		cpu_crit0 = "/thermal-zones/cpu-thermal0/trips/trip1";
		cpu_alert1 = "/thermal-zones/cpu-thermal1/trips/trip0";
		cpu_crit1 = "/thermal-zones/cpu-thermal1/trips/trip1";
		cpu_alert2 = "/thermal-zones/cpu-thermal2/trips/trip0";
		cpu_crit2 = "/thermal-zones/cpu-thermal2/trips/trip1";
		cpu_alert3 = "/thermal-zones/cpu-thermal3/trips/trip0";
		cpu_crit3 = "/thermal-zones/cpu-thermal3/trips/trip1";
		xo_board = "/clocks/xo_board";
		sleep_clk = "/clocks/sleep_clk";
		tcsr_mutex = "/hwlock";
		pm8994_s1 = "/rpm-glink/rpm_requests/pm8994-regulators/s1";
		pm8994_s2 = "/rpm-glink/rpm_requests/pm8994-regulators/s2";
		pm8994_s3 = "/rpm-glink/rpm_requests/pm8994-regulators/s3";
		pm8994_s4 = "/rpm-glink/rpm_requests/pm8994-regulators/s4";
		pm8994_s5 = "/rpm-glink/rpm_requests/pm8994-regulators/s5";
		pm8994_s6 = "/rpm-glink/rpm_requests/pm8994-regulators/s6";
		pm8994_s7 = "/rpm-glink/rpm_requests/pm8994-regulators/s7";
		pm8994_s8 = "/rpm-glink/rpm_requests/pm8994-regulators/s8";
		pm8994_s9 = "/rpm-glink/rpm_requests/pm8994-regulators/s9";
		pm8994_s10 = "/rpm-glink/rpm_requests/pm8994-regulators/s10";
		pm8994_s11 = "/rpm-glink/rpm_requests/pm8994-regulators/s11";
		pm8994_s12 = "/rpm-glink/rpm_requests/pm8994-regulators/s12";
		pm8994_l1 = "/rpm-glink/rpm_requests/pm8994-regulators/l1";
		pm8994_l2 = "/rpm-glink/rpm_requests/pm8994-regulators/l2";
		pm8994_l3 = "/rpm-glink/rpm_requests/pm8994-regulators/l3";
		pm8994_l4 = "/rpm-glink/rpm_requests/pm8994-regulators/l4";
		pm8994_l5 = "/rpm-glink/rpm_requests/pm8994-regulators/l5";
		pm8994_l6 = "/rpm-glink/rpm_requests/pm8994-regulators/l6";
		pm8994_l7 = "/rpm-glink/rpm_requests/pm8994-regulators/l7";
		pm8994_l8 = "/rpm-glink/rpm_requests/pm8994-regulators/l8";
		pm8994_l9 = "/rpm-glink/rpm_requests/pm8994-regulators/l9";
		pm8994_l10 = "/rpm-glink/rpm_requests/pm8994-regulators/l10";
		pm8994_l11 = "/rpm-glink/rpm_requests/pm8994-regulators/l11";
		pm8994_l12 = "/rpm-glink/rpm_requests/pm8994-regulators/l12";
		pm8994_l13 = "/rpm-glink/rpm_requests/pm8994-regulators/l13";
		pm8994_l14 = "/rpm-glink/rpm_requests/pm8994-regulators/l14";
		pm8994_l15 = "/rpm-glink/rpm_requests/pm8994-regulators/l15";
		pm8994_l16 = "/rpm-glink/rpm_requests/pm8994-regulators/l16";
		pm8994_l17 = "/rpm-glink/rpm_requests/pm8994-regulators/l17";
		pm8994_l18 = "/rpm-glink/rpm_requests/pm8994-regulators/l18";
		pm8994_l19 = "/rpm-glink/rpm_requests/pm8994-regulators/l19";
		pm8994_l20 = "/rpm-glink/rpm_requests/pm8994-regulators/l20";
		pm8994_l21 = "/rpm-glink/rpm_requests/pm8994-regulators/l21";
		pm8994_l22 = "/rpm-glink/rpm_requests/pm8994-regulators/l22";
		pm8994_l23 = "/rpm-glink/rpm_requests/pm8994-regulators/l23";
		pm8994_l24 = "/rpm-glink/rpm_requests/pm8994-regulators/l24";
		pm8994_l25 = "/rpm-glink/rpm_requests/pm8994-regulators/l25";
		pm8994_l26 = "/rpm-glink/rpm_requests/pm8994-regulators/l26";
		pm8994_l27 = "/rpm-glink/rpm_requests/pm8994-regulators/l27";
		pm8994_l28 = "/rpm-glink/rpm_requests/pm8994-regulators/l28";
		pm8994_l29 = "/rpm-glink/rpm_requests/pm8994-regulators/l29";
		pm8994_l30 = "/rpm-glink/rpm_requests/pm8994-regulators/l30";
		pm8994_l31 = "/rpm-glink/rpm_requests/pm8994-regulators/l31";
		pm8994_l32 = "/rpm-glink/rpm_requests/pm8994-regulators/l32";
		soc = "/soc";
		rpm_msg_ram = "/soc/memory@68000";
		tcsr_mutex_regs = "/soc/syscon@740000";
		intc = "/soc/interrupt-controller@9bc0000";
		apcs = "/soc/syscon@9820000";
		apcs_glb = "/soc/mailbox@9820000";
		gcc = "/soc/clock-controller@300000";
		kryocc = "/soc/clock-controller@6400000";
		blsp1_spi0 = "/soc/spi@07575000";
		blsp2_i2c0 = "/soc/i2c@075b5000";
		tsens0 = "/soc/thermal-sensor@4a8000";
		blsp2_uart1 = "/soc/serial@75b0000";
		blsp2_i2c1 = "/soc/i2c@075b6000";
		blsp2_uart2 = "/soc/serial@75b1000";
		blsp1_i2c2 = "/soc/i2c@07577000";
		blsp2_spi5 = "/soc/spi@075ba000";
		sdhc2 = "/soc/sdhci@74a4900";
		msmgpio = "/soc/pinctrl@1010000";
		blsp1_spi0_default = "/soc/pinctrl@1010000/blsp1_spi0_default";
		blsp1_spi0_sleep = "/soc/pinctrl@1010000/blsp1_spi0_sleep";
		blsp1_i2c2_default = "/soc/pinctrl@1010000/blsp1_i2c2_default";
		blsp1_i2c2_sleep = "/soc/pinctrl@1010000/blsp1_i2c2_sleep";
		blsp2_i2c0_default = "/soc/pinctrl@1010000/blsp2_i2c0";
		blsp2_i2c0_sleep = "/soc/pinctrl@1010000/blsp2_i2c0_sleep";
		blsp2_uart1_2pins_default = "/soc/pinctrl@1010000/blsp2_uart1_2pins";
		blsp2_uart1_2pins_sleep = "/soc/pinctrl@1010000/blsp2_uart1_2pins_sleep";
		blsp2_uart1_4pins_default = "/soc/pinctrl@1010000/blsp2_uart1_4pins";
		blsp2_uart1_4pins_sleep = "/soc/pinctrl@1010000/blsp2_uart1_4pins_sleep";
		blsp2_i2c1_default = "/soc/pinctrl@1010000/blsp2_i2c1";
		blsp2_i2c1_sleep = "/soc/pinctrl@1010000/blsp2_i2c1_sleep";
		blsp2_uart2_2pins_default = "/soc/pinctrl@1010000/blsp2_uart2_2pins";
		blsp2_uart2_2pins_sleep = "/soc/pinctrl@1010000/blsp2_uart2_2pins_sleep";
		blsp2_uart2_4pins_default = "/soc/pinctrl@1010000/blsp2_uart2_4pins";
		blsp2_uart2_4pins_sleep = "/soc/pinctrl@1010000/blsp2_uart2_4pins_sleep";
		blsp2_spi5_default = "/soc/pinctrl@1010000/blsp2_spi5_default";
		blsp2_spi5_sleep = "/soc/pinctrl@1010000/blsp2_spi5_sleep";
		sdc2_clk_on = "/soc/pinctrl@1010000/sdc2_clk_on";
		sdc2_clk_off = "/soc/pinctrl@1010000/sdc2_clk_off";
		sdc2_cmd_on = "/soc/pinctrl@1010000/sdc2_cmd_on";
		sdc2_cmd_off = "/soc/pinctrl@1010000/sdc2_cmd_off";
		sdc2_data_on = "/soc/pinctrl@1010000/sdc2_data_on";
		sdc2_data_off = "/soc/pinctrl@1010000/sdc2_data_off";
		sdc2_cd_on = "/soc/pinctrl@1010000/sdc2_cd_on";
		sdc2_cd_off = "/soc/pinctrl@1010000/sdc2_cd_off";
		spmi_bus = "/soc/qcom,spmi@400f000";
		pm8994_gpios = "/soc/qcom,spmi@400f000/pmic@0/gpios@c000";
		ls_exp_gpio_f = "/soc/qcom,spmi@400f000/pmic@0/gpios@c000/pm8994_gpio5";
		volume_up_gpio = "/soc/qcom,spmi@400f000/pmic@0/gpios@c000/pm8996_gpio2";
		usb3_vbus_det_gpio = "/soc/qcom,spmi@400f000/pmic@0/gpios@c000/pm8996_gpio22";
		pm8994_mpps = "/soc/qcom,spmi@400f000/pmic@0/mpps@a000";
		pmi8994_gpios = "/soc/qcom,spmi@400f000/pmic@2/gpios@c000";
		usb2_vbus_det_gpio = "/soc/qcom,spmi@400f000/pmic@2/gpios@c000/pmi8996_gpio6";
		mmcc = "/soc/clock-controller@8c0000";
		qusb2p_hstx_trim = "/soc/qfprom@74000/hstx_trim@24e";
		qusb2s_hstx_trim = "/soc/qfprom@74000/hstx_trim@24f";
		pciephy_0 = "/soc/phy@34000/lane@35000";
		pciephy_1 = "/soc/phy@34000/lane@36000";
		pciephy_2 = "/soc/phy@34000/lane@37000";
		ssusb_phy_0 = "/soc/phy@7410000/lane@7410200";
		hsusb_phy1 = "/soc/phy@7411000";
		hsusb_phy2 = "/soc/phy@7412000";
		usb2 = "/soc/usb@7600000";
		usb3 = "/soc/usb@6a00000";
		usb3_id = "/soc/usb3-id";
		usb2_id = "/soc/usb2-id";
		adsp_smp2p_out = "/adsp-smp2p/master-kernel";
		adsp_smp2p_in = "/adsp-smp2p/slave-kernel";
		modem_smp2p_out = "/modem-smp2p/master-kernel";
		modem_smp2p_in = "/modem-smp2p/slave-kernel";
		slpi_smp2p_in = "/smp2p-slpi/slave-kernel";
		slpi_smp2p_out = "/smp2p-slpi/master-kernel";
	};
};
